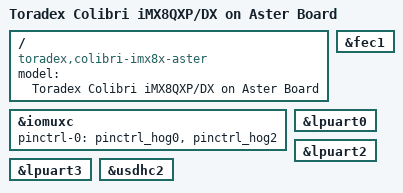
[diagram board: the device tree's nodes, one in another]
// SPDX-License-Identifier: GPL-2.0+ OR X11
/*
 * Copyright 2018-2019 Toradex
 */

/dts-v1/;

#include "imx8qxp-colibri.dtsi"

/ {
	model = "Toradex Colibri iMX8QXP/DX on Aster Board";
	compatible = "toradex,colibri-imx8x-aster",
		     "toradex,colibri-imx8x",
		     "fsl,imx8qxp";
};

/* Colibri Ethernet */
&fec1 {
	status = "okay";
};

&iomuxc {
	pinctrl-names = "default";
	pinctrl-0 = <&pinctrl_hog0>, <&pinctrl_hog2>;
};

/* Colibri UART_B */
&lpuart0 {
	status = "okay";
};

/* Colibri UART_C */
&lpuart2 {
	status = "okay";
};

/* Colibri UART_A */
&lpuart3 {
	status= "okay";
};

/* Colibri SDCard */
&usdhc2 {
	status = "okay";
};
